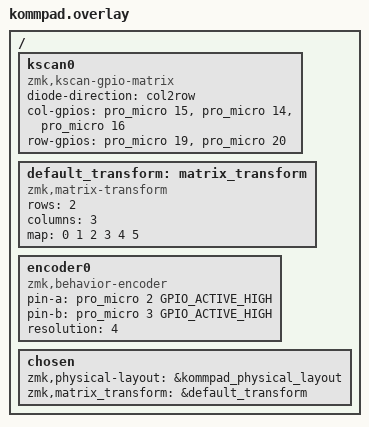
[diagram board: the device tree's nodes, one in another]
#include <dt-bindings/zmk/matrix_transform.h>

/ {
    kscan0: kscan0 {
        compatible = "zmk,kscan-gpio-matrix";
        diode-direction = "col2row";
        col-gpios = <&pro_micro 15 GPIO_ACTIVE_HIGH>,
                    <&pro_micro 14 GPIO_ACTIVE_HIGH>,
                    <&pro_micro 16 GPIO_ACTIVE_HIGH>;
        row-gpios = <&pro_micro 19 (GPIO_ACTIVE_HIGH | GPIO_PULL_DOWN)>,
                    <&pro_micro 20 (GPIO_ACTIVE_HIGH | GPIO_PULL_DOWN)>;
    };

    default_transform: matrix_transform {
        compatible = "zmk,matrix-transform";
        rows = <2>;
        columns = <3>;
        map = < 0 1 2
                3 4 5 >;
    };
    
    encoder0: encoder0 {
        compatible = "zmk,behavior-encoder";
        pin-a = <&pro_micro 2 GPIO_ACTIVE_HIGH>;
        pin-b = <&pro_micro 3 GPIO_ACTIVE_HIGH>;
        resolution = <4>;
    };

    chosen {
        zmk,physical-layout = &kommpad_physical_layout;
        zmk,matrix_transform = &default_transform;
    };
};
